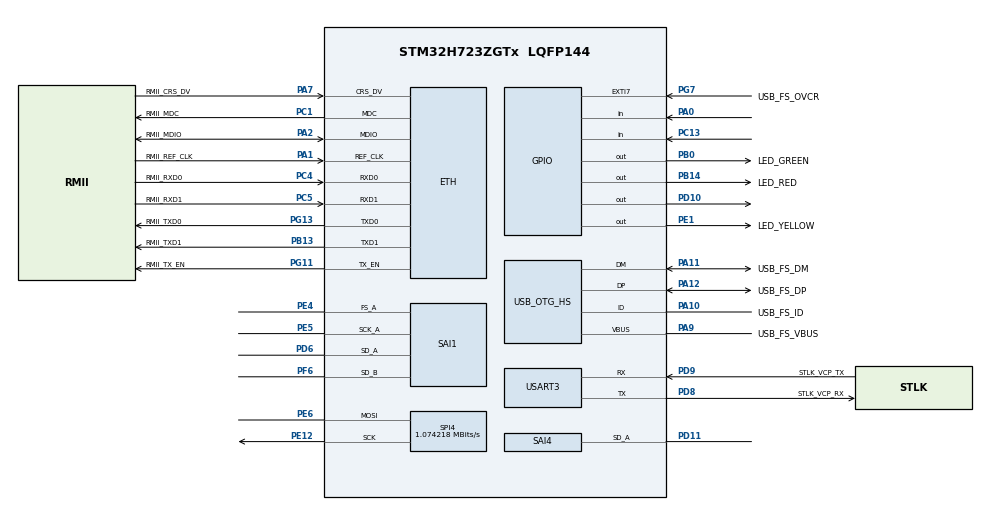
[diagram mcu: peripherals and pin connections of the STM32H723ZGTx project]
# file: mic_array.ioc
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Bdma.Request0=SAI4_A
Bdma.RequestsNb=1
Bdma.SAI4_A.0.Direction=DMA_PERIPH_TO_MEMORY
Bdma.SAI4_A.0.EventEnable=DISABLE
Bdma.SAI4_A.0.Instance=BDMA_Channel0
Bdma.SAI4_A.0.MemDataAlignment=DMA_MDATAALIGN_HALFWORD
Bdma.SAI4_A.0.MemInc=DMA_MINC_ENABLE
Bdma.SAI4_A.0.Mode=DMA_CIRCULAR
Bdma.SAI4_A.0.PeriphDataAlignment=DMA_PDATAALIGN_HALFWORD
Bdma.SAI4_A.0.PeriphInc=DMA_PINC_DISABLE
Bdma.SAI4_A.0.Polarity=HAL_DMAMUX_REQ_GEN_RISING
Bdma.SAI4_A.0.Priority=DMA_PRIORITY_LOW
Bdma.SAI4_A.0.RequestNumber=1
Bdma.SAI4_A.0.SignalID=NONE
Bdma.SAI4_A.0.SyncEnable=DISABLE
Bdma.SAI4_A.0.SyncPolarity=HAL_DMAMUX_SYNC_NO_EVENT
Bdma.SAI4_A.0.SyncRequestNumber=1
Bdma.SAI4_A.0.SyncSignalID=NONE
CORTEX_M7.AccessPermission-Cortex_Memory_Protection_Unit_Region0_Settings=MPU_REGION_FULL_ACCESS
CORTEX_M7.AccessPermission-Cortex_Memory_Protection_Unit_Region1_Settings=MPU_REGION_FULL_ACCESS
CORTEX_M7.BaseAddress-Cortex_Memory_Protection_Unit_Region0_Settings=0x30007000
CORTEX_M7.BaseAddress-Cortex_Memory_Protection_Unit_Region1_Settings=0x38003000
CORTEX_M7.CPU_DCache=Enabled
CORTEX_M7.CPU_ICache=Enabled
CORTEX_M7.DisableExec-Cortex_Memory_Protection_Unit_Region0_Settings=MPU_INSTRUCTION_ACCESS_DISABLE
CORTEX_M7.DisableExec-Cortex_Memory_Protection_Unit_Region1_Settings=MPU_INSTRUCTION_ACCESS_DISABLE
CORTEX_M7.Enable-Cortex_Memory_Protection_Unit_Region0_Settings=MPU_REGION_ENABLE
CORTEX_M7.Enable-Cortex_Memory_Protection_Unit_Region1_Settings=MPU_REGION_ENABLE
CORTEX_M7.IsShareable-Cortex_Memory_Protection_Unit_Region0_Settings=MPU_ACCESS_SHAREABLE
CORTEX_M7.IsShareable-Cortex_Memory_Protection_Unit_Region1_Settings=MPU_ACCESS_SHAREABLE
CORTEX_M7.MPU_Control=MPU_PRIVILEGED_DEFAULT
CORTEX_M7.Size-Cortex_Memory_Protection_Unit_Region0_Settings=MPU_REGION_SIZE_32KB
CORTEX_M7.Size-Cortex_Memory_Protection_Unit_Region1_Settings=MPU_REGION_SIZE_4KB
Dma.Request0=SAI1_A
Dma.Request1=SAI1_B
Dma.SAI1_A.0.Direction=DMA_PERIPH_TO_MEMORY
Dma.SAI1_A.0.EventEnable=DISABLE
Dma.SAI1_A.0.FIFOMode=DMA_FIFOMODE_DISABLE
Dma.SAI1_A.0.Instance=DMA1_Stream2
Dma.SAI1_A.0.MemDataAlignment=DMA_MDATAALIGN_HALFWORD
Dma.SAI1_A.0.MemInc=DMA_MINC_ENABLE
Dma.SAI1_A.0.Mode=DMA_CIRCULAR
Dma.SAI1_A.0.PeriphDataAlignment=DMA_PDATAALIGN_HALFWORD
Dma.SAI1_A.0.PeriphInc=DMA_PINC_DISABLE
Dma.SAI1_A.0.Polarity=HAL_DMAMUX_REQ_GEN_RISING
Dma.SAI1_A.0.Priority=DMA_PRIORITY_LOW
Dma.SAI1_A.0.RequestNumber=1
Dma.SAI1_A.0.SignalID=NONE
Dma.SAI1_A.0.SyncEnable=DISABLE
Dma.SAI1_A.0.SyncPolarity=HAL_DMAMUX_SYNC_NO_EVENT
Dma.SAI1_A.0.SyncRequestNumber=1
Dma.SAI1_A.0.SyncSignalID=NONE
Dma.SAI1_B.1.Direction=DMA_PERIPH_TO_MEMORY
Dma.SAI1_B.1.EventEnable=DISABLE
Dma.SAI1_B.1.FIFOMode=DMA_FIFOMODE_DISABLE
Dma.SAI1_B.1.Instance=DMA1_Stream3
Dma.SAI1_B.1.MemDataAlignment=DMA_MDATAALIGN_HALFWORD
Dma.SAI1_B.1.MemInc=DMA_MINC_ENABLE
Dma.SAI1_B.1.Mode=DMA_CIRCULAR
Dma.SAI1_B.1.PeriphDataAlignment=DMA_PDATAALIGN_HALFWORD
Dma.SAI1_B.1.PeriphInc=DMA_PINC_DISABLE
Dma.SAI1_B.1.Polarity=HAL_DMAMUX_REQ_GEN_RISING
Dma.SAI1_B.1.Priority=DMA_PRIORITY_LOW
Dma.SAI1_B.1.RequestNumber=1
Dma.SAI1_B.1.SignalID=NONE
Dma.SAI1_B.1.SyncEnable=DISABLE
Dma.SAI1_B.1.SyncPolarity=HAL_DMAMUX_SYNC_NO_EVENT
Dma.SAI1_B.1.SyncRequestNumber=1
Dma.SAI1_B.1.SyncSignalID=NONE
ETH.MediaInterface=HAL_ETH_RMII_MODE
Mcu.Family=STM32H7
Mcu.Name=STM32H723ZGTx
Mcu.Package=LQFP144
NVIC.BDMA_Channel0_IRQn=true\:0\:0\:false\:false\:true\:false\:true\:true
NVIC.DMA1_Stream2_IRQn=true\:0\:0\:false\:false\:true\:false\:true\:true
NVIC.DMA1_Stream3_IRQn=true\:0\:0\:false\:false\:true\:false\:true\:true
NVIC.PriorityGroup=NVIC_PRIORITYGROUP_4
NVIC.TIM1_UP_IRQn=true\:15\:0\:false\:false\:true\:false\:true\:true
NVIC.TimeBase=TIM1_UP_IRQn
NVIC.TimeBaseIP=TIM1
PA0.Signal=GPIO_Input
PA1.GPIO_Label=RMII_REF_CLK
PA1.Mode=RMII
PA1.Signal=ETH_REF_CLK
PA10.GPIO_Label=USB_FS_ID
PA10.Mode=OTG/Dual_Role_Device_FS
PA10.Signal=USB_OTG_HS_ID
PA11.GPIO_Label=USB_FS_DM
PA11.Mode=OTG/Dual_Role_Device_FS
PA11.Signal=USB_OTG_HS_DM
PA12.GPIO_Label=USB_FS_DP
PA12.Mode=OTG/Dual_Role_Device_FS
PA12.Signal=USB_OTG_HS_DP
PA13(JTMS/SWDIO).GPIO_Label=SWDIO
PA13(JTMS/SWDIO).Mode=Trace_Asynchronous_SW
PA13(JTMS/SWDIO).Signal=DEBUG_JTMS-SWDIO
PA14(JTCK/SWCLK).GPIO_Label=SWCLK
PA14(JTCK/SWCLK).Mode=Trace_Asynchronous_SW
PA14(JTCK/SWCLK).Signal=DEBUG_JTCK-SWCLK
PA15(JTDI).Signal=I2S6_WS
PA2.GPIO_Label=RMII_MDIO
PA2.Mode=RMII
PA2.Signal=ETH_MDIO
PA7.GPIO_Label=RMII_CRS_DV
PA7.Mode=RMII
PA7.Signal=ETH_CRS_DV
PA9.GPIO_Label=USB_FS_VBUS
PA9.Mode=Activate_VBUS_FS
PA9.Signal=USB_OTG_HS_VBUS
PB0.GPIO_Label=LED_GREEN
PB0.Signal=GPIO_Output
PB13.GPIO_Label=RMII_TXD1
PB13.Mode=RMII
PB13.Signal=ETH_TXD1
PB14.GPIO_Label=LED_RED
PB14.Signal=GPIO_Output
PB3(JTDO/TRACESWO).GPIO_Label=SWO
PB3(JTDO/TRACESWO).Mode=Trace_Asynchronous_SW
PB3(JTDO/TRACESWO).Signal=DEBUG_JTDO-SWO
PC1.GPIO_Label=RMII_MDC
PC1.Mode=RMII
PC1.Signal=ETH_MDC
PC13.Signal=GPIO_Input
PC14-OSC32_IN.Mode=LSE-External-Oscillator
PC14-OSC32_IN.Signal=RCC_OSC32_IN
PC15-OSC32_OUT.Mode=LSE-External-Oscillator
PC15-OSC32_OUT.Signal=RCC_OSC32_OUT
PC4.GPIO_Label=RMII_RXD0
PC4.Mode=RMII
PC4.Signal=ETH_RXD0
PC5.GPIO_Label=RMII_RXD1
PC5.Mode=RMII
PC5.Signal=ETH_RXD1
PD10.Signal=GPIO_Output
PD11.Mode=SAI_A_SyncSlave
PD11.Signal=SAI4_SD_A
PD6.Mode=SAI_A_Master
PD6.Signal=SAI1_SD_A
PD8.GPIO_Label=STLK_VCP_RX
PD8.Mode=Asynchronous
PD8.Signal=USART3_TX
PD9.GPIO_Label=STLK_VCP_TX
PD9.Mode=Asynchronous
PD9.Signal=USART3_RX
PE1.GPIO_Label=LED_YELLOW
PE1.Signal=GPIO_Output
PE12.Mode=Simplex_Bidirectional_Master
PE12.Signal=SPI4_SCK
PE4.Mode=SAI_A_Master
PE4.Signal=SAI1_FS_A
PE5.Mode=SAI_A_Master
PE5.Signal=SAI1_SCK_A
PE6.Mode=Simplex_Bidirectional_Master
PE6.Signal=SPI4_MOSI
PF6.Mode=SAI_B_SyncSlave
PF6.Signal=SAI1_SD_B
PG11.GPIO_Label=RMII_TX_EN
PG11.Mode=RMII
PG11.Signal=ETH_TX_EN
PG13.GPIO_Label=RMII_TXD0
PG13.Mode=RMII
PG13.Signal=ETH_TXD0
PG7.GPIO_Label=USB_FS_OVCR
PG7.Signal=GPXTI7
PH0-OSC_IN.GPIO_Label=MCO
PH0-OSC_IN.Mode=HSE-External-Clock-Source
PH0-OSC_IN.Signal=RCC_OSC_IN
PH1-OSC_OUT.Signal=RCC_OSC_OUT
ProjectManager.HeapSize=0x200
ProjectManager.StackSize=0x400
ProjectManager.TargetToolchain=STM32CubeIDE
RCC.ADCFreq_Value=76000000
RCC.APB1Freq_Value=137500000
RCC.APB2Freq_Value=137500000
RCC.APB3Freq_Value=137500000
RCC.APB4Freq_Value=137500000
RCC.CortexFreq_Value=550000000
RCC.D1PPRE=RCC_APB3_DIV2
RCC.D2PPRE1=RCC_APB1_DIV2
RCC.D2PPRE2=RCC_APB2_DIV2
RCC.D3PPRE=RCC_APB4_DIV2
RCC.DIVM1=4
RCC.DIVM2=1
RCC.DIVN1=275
RCC.DIVN2=19
RCC.DIVP1=1
RCC.DIVQ1=4
RCC.HCLKFreq_Value=275000000
RCC.HPRE=RCC_HCLK_DIV2
RCC.HSE_VALUE=8000000
RCC.PLLFRACN=0
RCC.PLLSourceVirtual=RCC_PLLSOURCE_HSE
RCC.SYSCLKFreq_VALUE=550000000
RCC.SYSCLKSource=RCC_SYSCLKSOURCE_PLLCLK
RCC.USBCLockSelection=RCC_USBCLKSOURCE_HSI48
RCC.USBFreq_Value=48000000
SAI1.AudioFrequency-SAI_A_Master=SAI_AUDIO_FREQUENCY_48K
SAI1.AudioMode-SAI_A_Master=SAI_MODEMASTER_RX
SAI1.BasicDataSize-SAI_A_Master=SAI_PROTOCOL_DATASIZE_16BITEXTENDED
SAI1.BasicDataSize-SAI_B_SyncSlave=SAI_PROTOCOL_DATASIZE_16BITEXTENDED
SAI1.BasicProtocol-SAI_A_Master=SAI_I2S_STANDARD
SAI1.ErrorAudioFreq-SAI_A_Master=11.89 %
SAI1.InitProtocol-SAI_A_Master=Enable
SAI1.InitProtocol-SAI_B_SyncSlave=Enable
SAI1.Instance-SAI_A_Master=SAI$Index_Block_A
SAI1.Instance-SAI_B_SyncSlave=SAI$Index_Block_B
SAI1.MckOutput-SAI_A_Master=SAI_MCK_OUTPUT_DISABLE
SAI1.RealAudioFreq-SAI_A_Master=53.71 KHz
SAI1.SynchroExt=SAI_SYNCEXT_OUTBLOCKA_ENABLE
SAI1.VirtualMode-SAI_A_Master=VM_MASTER
SAI1.VirtualMode-SAI_B_SyncSlave=VM_SLAVE
SAI1.VirtualProtocol-SAI_A_BASIC=VM_BASIC_PROTOCOL
SAI1.VirtualProtocol-SAI_B_BASIC=VM_BASIC_PROTOCOL
SAI4.BasicDataSize-SAI_A_SyncSlave=SAI_PROTOCOL_DATASIZE_16BITEXTENDED
SAI4.InitProtocol-SAI_A_SyncSlave=Enable
SAI4.Instance-SAI_A_SyncSlave=SAI$Index_Block_A
SAI4.Synchro_A=SAI_SYNCHRONOUS_EXT_SAI1
SAI4.VirtualMode-SAI_A_SyncSlave=VM_SLAVE
SAI4.VirtualProtocol-SAI_A_BASIC=VM_BASIC_PROTOCOL
SPI4.BaudRatePrescaler=SPI_BAUDRATEPRESCALER_128
SPI4.CalculateBaudRate=1.074218 MBits/s
SPI4.DataSize=SPI_DATASIZE_8BIT
SPI4.Direction=SPI_DIRECTION_1LINE
SPI4.Mode=SPI_MODE_MASTER
SPI4.VirtualType=VM_MASTER
USART3.VirtualMode-Asynchronous=VM_ASYNC
USB_OTG_HS.VirtualMode-OTG/Dual_Role_Device_FS=Device_Role_Device_FS
VP_MEMORYMAP_VS_MEMORYMAP.Mode=CurAppReg
VP_SAI1_VP_$IpInstance_SAIA_SAI_BASIC.Mode=SAI_A_BASIC
VP_SAI1_VP_$IpInstance_SAIB_SAI_BASIC.Mode=SAI_B_BASIC
VP_SAI1_VP_$IpInstance_SYNCHRO_EXTERNAL.Mode=SynchroExternal
VP_SAI4_VP_$IpInstance_SAIA_SAI_BASIC.Mode=SAI_A_BASIC
VP_SYS_VS_tim1.Mode=TIM1
VP_USB_OTG_HS1_USB_OTG_HS_DR.Mode=activate
board=NUCLEO-H723ZG

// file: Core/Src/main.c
/* USER CODE BEGIN Header */
/**
 ******************************************************************************
 * @file           : main.c
 * @brief          : Main program body
 ******************************************************************************
 * @attention
 *
 * Copyright (c) 2026 STMicroelectronics.
 * All rights reserved.
 *
 * This software is licensed under terms that can be found in the LICENSE file
 * in the root directory of this software component.
 * If no LICENSE file comes with this software, it is provided AS-IS.
 *
 ******************************************************************************
 */
/* USER CODE END Header */
#include "main.h"
#include "string.h"

/* USER CODE BEGIN Includes */
//#include "app.h"
#include "app_mic_test.h"

/* USER CODE END Includes */

#if defined ( __ICCARM__ ) /*!< IAR Compiler */
#pragma location=0x30000000
ETH_DMADescTypeDef  DMARxDscrTab[ETH_RX_DESC_CNT]; /* Ethernet Rx DMA Descriptors */
#pragma location=0x30000080
ETH_DMADescTypeDef  DMATxDscrTab[ETH_TX_DESC_CNT]; /* Ethernet Tx DMA Descriptors */

#elif defined ( __CC_ARM )  /* MDK ARM Compiler */

__attribute__((at(0x30000000))) ETH_DMADescTypeDef  DMARxDscrTab[ETH_RX_DESC_CNT]; /* Ethernet Rx DMA Descriptors */
__attribute__((at(0x30000080))) ETH_DMADescTypeDef  DMATxDscrTab[ETH_TX_DESC_CNT]; /* Ethernet Tx DMA Descriptors */

#elif defined ( __GNUC__ ) /* GNU Compiler */

ETH_DMADescTypeDef DMARxDscrTab[ETH_RX_DESC_CNT] __attribute__((section(".RxDescripSection"))); /* Ethernet Rx DMA Descriptors */
ETH_DMADescTypeDef DMATxDscrTab[ETH_TX_DESC_CNT] __attribute__((section(".TxDescripSection")));   /* Ethernet Tx DMA Descriptors */
#endif

ETH_TxPacketConfig TxConfig;

ETH_HandleTypeDef heth;

SAI_HandleTypeDef hsai_BlockA1;
SAI_HandleTypeDef hsai_BlockB1;
SAI_HandleTypeDef hsai_BlockA4;
DMA_HandleTypeDef hdma_sai1_a;
DMA_HandleTypeDef hdma_sai1_b;
DMA_HandleTypeDef hdma_sai4_a;

SPI_HandleTypeDef hspi4;

UART_HandleTypeDef huart3;

PCD_HandleTypeDef hpcd_USB_OTG_HS;
HCD_HandleTypeDef hhcd_USB_OTG_HS;

void SystemClock_Config(void);
static void MPU_Config(void);
static void MX_GPIO_Init(void);
static void MX_DMA_Init(void);
static void MX_BDMA_Init(void);
static void MX_ETH_Init(void);
static void MX_USART3_UART_Init(void);
static void MX_USB_OTG_HS_PCD_Init(void);
static void MX_SPI4_Init(void);
static void MX_SAI1_Init(void);
static void MX_SAI4_Init(void);

int main(void)
{

  /* MPU Configuration--------------------------------------------------------*/
  MPU_Config();

  /* Enable the CPU Cache */

  /* Enable I-Cache---------------------------------------------------------*/
  SCB_EnableICache();

  /* Enable D-Cache---------------------------------------------------------*/
  SCB_EnableDCache();

  /* MCU Configuration--------------------------------------------------------*/

  /* Reset of all peripherals, Initializes the Flash interface and the Systick. */
  HAL_Init();

  /* Configure the system clock */
  SystemClock_Config();

  /* USER CODE BEGIN SysInit */

  // Ensure D3 memory region stays powered on when I'm debugging
  PWR->CPUCR |= PWR_CPUCR_RUN_D3;

  /* USER CODE END SysInit */

  /* Initialize all configured peripherals */
  MX_GPIO_Init();
  MX_DMA_Init();
  MX_BDMA_Init();
  MX_ETH_Init();
  MX_USART3_UART_Init();
  MX_USB_OTG_HS_PCD_Init();
  MX_SPI4_Init();
  MX_SAI1_Init();
  MX_SAI4_Init();
  /* USER CODE BEGIN 2 */

  HAL_StatusTypeDef ret = app_init();
  if (ret != HAL_OK)
  {
      while (1)
      {

      }
  }

  /* USER CODE END 2 */

  /* Infinite loop */
  /* USER CODE BEGIN WHILE */
    app_loop();
    /* USER CODE END WHILE */

}

void SystemClock_Config(void)
{
  RCC_OscInitTypeDef RCC_OscInitStruct = {0};
  RCC_ClkInitTypeDef RCC_ClkInitStruct = {0};

  /** Supply configuration update enable
  */
  HAL_PWREx_ConfigSupply(PWR_LDO_SUPPLY);

  /** Configure the main internal regulator output voltage
  */
  __HAL_PWR_VOLTAGESCALING_CONFIG(PWR_REGULATOR_VOLTAGE_SCALE0);

  while(!__HAL_PWR_GET_FLAG(PWR_FLAG_VOSRDY)) {}

  /** Initializes the RCC Oscillators according to the specified parameters
  * in the RCC_OscInitTypeDef structure.
  */
  RCC_OscInitStruct.OscillatorType = RCC_OSCILLATORTYPE_HSI48|RCC_OSCILLATORTYPE_HSE;
  RCC_OscInitStruct.HSEState = RCC_HSE_BYPASS;
  RCC_OscInitStruct.HSI48State = RCC_HSI48_ON;
  RCC_OscInitStruct.PLL.PLLState = RCC_PLL_ON;
  RCC_OscInitStruct.PLL.PLLSource = RCC_PLLSOURCE_HSE;
  RCC_OscInitStruct.PLL.PLLM = 4;
  RCC_OscInitStruct.PLL.PLLN = 275;
  RCC_OscInitStruct.PLL.PLLP = 1;
  RCC_OscInitStruct.PLL.PLLQ = 4;
  RCC_OscInitStruct.PLL.PLLR = 2;
  RCC_OscInitStruct.PLL.PLLRGE = RCC_PLL1VCIRANGE_1;
  RCC_OscInitStruct.PLL.PLLVCOSEL = RCC_PLL1VCOWIDE;
  RCC_OscInitStruct.PLL.PLLFRACN = 0;
  if (HAL_RCC_OscConfig(&RCC_OscInitStruct) != HAL_OK)
  {
    Error_Handler();
  }

  /** Initializes the CPU, AHB and APB buses clocks
  */
  RCC_ClkInitStruct.ClockType = RCC_CLOCKTYPE_HCLK|RCC_CLOCKTYPE_SYSCLK
                              |RCC_CLOCKTYPE_PCLK1|RCC_CLOCKTYPE_PCLK2
                              |RCC_CLOCKTYPE_D3PCLK1|RCC_CLOCKTYPE_D1PCLK1;
  RCC_ClkInitStruct.SYSCLKSource = RCC_SYSCLKSOURCE_PLLCLK;
  RCC_ClkInitStruct.SYSCLKDivider = RCC_SYSCLK_DIV1;
  RCC_ClkInitStruct.AHBCLKDivider = RCC_HCLK_DIV2;
  RCC_ClkInitStruct.APB3CLKDivider = RCC_APB3_DIV2;
  RCC_ClkInitStruct.APB1CLKDivider = RCC_APB1_DIV2;
  RCC_ClkInitStruct.APB2CLKDivider = RCC_APB2_DIV2;
  RCC_ClkInitStruct.APB4CLKDivider = RCC_APB4_DIV2;

  if (HAL_RCC_ClockConfig(&RCC_ClkInitStruct, FLASH_LATENCY_3) != HAL_OK)
  {
    Error_Handler();
  }
}

static void MX_ETH_Init(void)
{

   static uint8_t MACAddr[6];

  heth.Instance = ETH;
  MACAddr[0] = 0x00;
  MACAddr[1] = 0x80;
  MACAddr[2] = 0xE1;
  MACAddr[3] = 0x00;
  MACAddr[4] = 0x00;
  MACAddr[5] = 0x00;
  heth.Init.MACAddr = &MACAddr[0];
  heth.Init.MediaInterface = HAL_ETH_RMII_MODE;
  heth.Init.TxDesc = DMATxDscrTab;
  heth.Init.RxDesc = DMARxDscrTab;
  heth.Init.RxBuffLen = 1536;

  if (HAL_ETH_Init(&heth) != HAL_OK)
  {
    Error_Handler();
  }

  memset(&TxConfig, 0 , sizeof(ETH_TxPacketConfig));
  TxConfig.Attributes = ETH_TX_PACKETS_FEATURES_CSUM | ETH_TX_PACKETS_FEATURES_CRCPAD;
  TxConfig.ChecksumCtrl = ETH_CHECKSUM_IPHDR_PAYLOAD_INSERT_PHDR_CALC;
  TxConfig.CRCPadCtrl = ETH_CRC_PAD_INSERT;

}

static void MX_SAI1_Init(void)
{

  hsai_BlockA1.Instance = SAI1_Block_A;
  hsai_BlockA1.Init.AudioMode = SAI_MODEMASTER_RX;
  hsai_BlockA1.Init.Synchro = SAI_ASYNCHRONOUS;
  hsai_BlockA1.Init.OutputDrive = SAI_OUTPUTDRIVE_DISABLE;
  hsai_BlockA1.Init.NoDivider = SAI_MASTERDIVIDER_ENABLE;
  hsai_BlockA1.Init.FIFOThreshold = SAI_FIFOTHRESHOLD_EMPTY;
  hsai_BlockA1.Init.AudioFrequency = SAI_AUDIO_FREQUENCY_48K;
  hsai_BlockA1.Init.SynchroExt = SAI_SYNCEXT_OUTBLOCKA_ENABLE;
  hsai_BlockA1.Init.MonoStereoMode = SAI_STEREOMODE;
  hsai_BlockA1.Init.CompandingMode = SAI_NOCOMPANDING;
  if (HAL_SAI_InitProtocol(&hsai_BlockA1, SAI_I2S_STANDARD, SAI_PROTOCOL_DATASIZE_16BITEXTENDED, 2) != HAL_OK)
  {
    Error_Handler();
  }
  hsai_BlockB1.Instance = SAI1_Block_B;
  hsai_BlockB1.Init.AudioMode = SAI_MODESLAVE_RX;
  hsai_BlockB1.Init.Synchro = SAI_SYNCHRONOUS;
  hsai_BlockB1.Init.OutputDrive = SAI_OUTPUTDRIVE_DISABLE;
  hsai_BlockB1.Init.FIFOThreshold = SAI_FIFOTHRESHOLD_EMPTY;
  hsai_BlockB1.Init.SynchroExt = SAI_SYNCEXT_OUTBLOCKA_ENABLE;
  hsai_BlockB1.Init.MonoStereoMode = SAI_STEREOMODE;
  hsai_BlockB1.Init.CompandingMode = SAI_NOCOMPANDING;
  hsai_BlockB1.Init.TriState = SAI_OUTPUT_NOTRELEASED;
  if (HAL_SAI_InitProtocol(&hsai_BlockB1, SAI_I2S_STANDARD, SAI_PROTOCOL_DATASIZE_16BITEXTENDED, 2) != HAL_OK)
  {
    Error_Handler();
  }

}

static void MX_SAI4_Init(void)
{

  hsai_BlockA4.Instance = SAI4_Block_A;
  hsai_BlockA4.Init.AudioMode = SAI_MODESLAVE_RX;
  hsai_BlockA4.Init.Synchro = SAI_SYNCHRONOUS_EXT_SAI1;
  hsai_BlockA4.Init.OutputDrive = SAI_OUTPUTDRIVE_DISABLE;
  hsai_BlockA4.Init.FIFOThreshold = SAI_FIFOTHRESHOLD_EMPTY;
  hsai_BlockA4.Init.MonoStereoMode = SAI_STEREOMODE;
  hsai_BlockA4.Init.CompandingMode = SAI_NOCOMPANDING;
  hsai_BlockA4.Init.TriState = SAI_OUTPUT_NOTRELEASED;
  if (HAL_SAI_InitProtocol(&hsai_BlockA4, SAI_I2S_STANDARD, SAI_PROTOCOL_DATASIZE_16BITEXTENDED, 2) != HAL_OK)
  {
    Error_Handler();
  }

}

static void MX_SPI4_Init(void)
{

  /* SPI4 parameter configuration*/
  hspi4.Instance = SPI4;
  hspi4.Init.Mode = SPI_MODE_MASTER;
  hspi4.Init.Direction = SPI_DIRECTION_1LINE;
  hspi4.Init.DataSize = SPI_DATASIZE_8BIT;
  hspi4.Init.CLKPolarity = SPI_POLARITY_LOW;
  hspi4.Init.CLKPhase = SPI_PHASE_1EDGE;
  hspi4.Init.NSS = SPI_NSS_SOFT;
  hspi4.Init.BaudRatePrescaler = SPI_BAUDRATEPRESCALER_128;
  hspi4.Init.FirstBit = SPI_FIRSTBIT_MSB;
  hspi4.Init.TIMode = SPI_TIMODE_DISABLE;
  hspi4.Init.CRCCalculation = SPI_CRCCALCULATION_DISABLE;
  hspi4.Init.CRCPolynomial = 0x0;
  hspi4.Init.NSSPMode = SPI_NSS_PULSE_ENABLE;
  hspi4.Init.NSSPolarity = SPI_NSS_POLARITY_LOW;
  hspi4.Init.FifoThreshold = SPI_FIFO_THRESHOLD_01DATA;
  hspi4.Init.TxCRCInitializationPattern = SPI_CRC_INITIALIZATION_ALL_ZERO_PATTERN;
  hspi4.Init.RxCRCInitializationPattern = SPI_CRC_INITIALIZATION_ALL_ZERO_PATTERN;
  hspi4.Init.MasterSSIdleness = SPI_MASTER_SS_IDLENESS_00CYCLE;
  hspi4.Init.MasterInterDataIdleness = SPI_MASTER_INTERDATA_IDLENESS_00CYCLE;
  hspi4.Init.MasterReceiverAutoSusp = SPI_MASTER_RX_AUTOSUSP_DISABLE;
  hspi4.Init.MasterKeepIOState = SPI_MASTER_KEEP_IO_STATE_DISABLE;
  hspi4.Init.IOSwap = SPI_IO_SWAP_DISABLE;
  if (HAL_SPI_Init(&hspi4) != HAL_OK)
  {
    Error_Handler();
  }

}

static void MX_USART3_UART_Init(void)
{

  huart3.Instance = USART3;
  huart3.Init.BaudRate = 115200;
  huart3.Init.WordLength = UART_WORDLENGTH_8B;
  huart3.Init.StopBits = UART_STOPBITS_1;
  huart3.Init.Parity = UART_PARITY_NONE;
  huart3.Init.Mode = UART_MODE_TX_RX;
  huart3.Init.HwFlowCtl = UART_HWCONTROL_NONE;
  huart3.Init.OverSampling = UART_OVERSAMPLING_16;
  huart3.Init.OneBitSampling = UART_ONE_BIT_SAMPLE_DISABLE;
  huart3.Init.ClockPrescaler = UART_PRESCALER_DIV1;
  huart3.AdvancedInit.AdvFeatureInit = UART_ADVFEATURE_NO_INIT;
  if (HAL_UART_Init(&huart3) != HAL_OK)
  {
    Error_Handler();
  }
  if (HAL_UARTEx_SetTxFifoThreshold(&huart3, UART_TXFIFO_THRESHOLD_1_8) != HAL_OK)
  {
    Error_Handler();
  }
  if (HAL_UARTEx_SetRxFifoThreshold(&huart3, UART_RXFIFO_THRESHOLD_1_8) != HAL_OK)
  {
    Error_Handler();
  }
  if (HAL_UARTEx_DisableFifoMode(&huart3) != HAL_OK)
  {
    Error_Handler();
  }

}

static void MX_USB_OTG_HS_PCD_Init(void)
{

  hpcd_USB_OTG_HS.Instance = USB_OTG_HS;
  hpcd_USB_OTG_HS.Init.dev_endpoints = 9;
  hpcd_USB_OTG_HS.Init.speed = PCD_SPEED_FULL;
  hpcd_USB_OTG_HS.Init.dma_enable = DISABLE;
  hpcd_USB_OTG_HS.Init.phy_itface = USB_OTG_EMBEDDED_PHY;
  hpcd_USB_OTG_HS.Init.Sof_enable = DISABLE;
  hpcd_USB_OTG_HS.Init.low_power_enable = DISABLE;
  hpcd_USB_OTG_HS.Init.lpm_enable = DISABLE;
  hpcd_USB_OTG_HS.Init.vbus_sensing_enable = ENABLE;
  hpcd_USB_OTG_HS.Init.use_dedicated_ep1 = DISABLE;
  hpcd_USB_OTG_HS.Init.use_external_vbus = DISABLE;
  if (HAL_PCD_Init(&hpcd_USB_OTG_HS) != HAL_OK)
  {
    Error_Handler();
  }

}

void MX_USB_OTG_HS_HCD_Init(void)
{

  hhcd_USB_OTG_HS.Instance = USB_OTG_HS;
  hhcd_USB_OTG_HS.Init.Host_channels = 16;
  hhcd_USB_OTG_HS.Init.speed = HCD_SPEED_FULL;
  hhcd_USB_OTG_HS.Init.dma_enable = DISABLE;
  hhcd_USB_OTG_HS.Init.phy_itface = USB_OTG_EMBEDDED_PHY;
  hhcd_USB_OTG_HS.Init.Sof_enable = DISABLE;
  hhcd_USB_OTG_HS.Init.low_power_enable = DISABLE;
  if (HAL_HCD_Init(&hhcd_USB_OTG_HS) != HAL_OK)
  {
    Error_Handler();
  }

}

static void MX_BDMA_Init(void)
{

  /* DMA controller clock enable */
  __HAL_RCC_BDMA_CLK_ENABLE();

  /* DMA interrupt init */
  /* BDMA_Channel0_IRQn interrupt configuration */
  HAL_NVIC_SetPriority(BDMA_Channel0_IRQn, 0, 0);
  HAL_NVIC_EnableIRQ(BDMA_Channel0_IRQn);

}

static void MX_DMA_Init(void)
{

  /* DMA controller clock enable */
  __HAL_RCC_DMA1_CLK_ENABLE();

  /* DMA interrupt init */
  /* DMA1_Stream2_IRQn interrupt configuration */
  HAL_NVIC_SetPriority(DMA1_Stream2_IRQn, 0, 0);
  HAL_NVIC_EnableIRQ(DMA1_Stream2_IRQn);
  /* DMA1_Stream3_IRQn interrupt configuration */
  HAL_NVIC_SetPriority(DMA1_Stream3_IRQn, 0, 0);
  HAL_NVIC_EnableIRQ(DMA1_Stream3_IRQn);

}

static void MX_GPIO_Init(void)
{
  GPIO_InitTypeDef GPIO_InitStruct = {0};

  /* GPIO Ports Clock Enable */
  __HAL_RCC_GPIOE_CLK_ENABLE();
  __HAL_RCC_GPIOC_CLK_ENABLE();
  __HAL_RCC_GPIOF_CLK_ENABLE();
  __HAL_RCC_GPIOH_CLK_ENABLE();
  __HAL_RCC_GPIOA_CLK_ENABLE();
  __HAL_RCC_GPIOB_CLK_ENABLE();
  __HAL_RCC_GPIOD_CLK_ENABLE();
  __HAL_RCC_GPIOG_CLK_ENABLE();

  /*Configure GPIO pin Output Level */
  HAL_GPIO_WritePin(GPIOB, LED_GREEN_Pin|LED_RED_Pin, GPIO_PIN_RESET);

  /*Configure GPIO pin Output Level */
  HAL_GPIO_WritePin(GPIOD, GPIO_PIN_10, GPIO_PIN_RESET);

  /*Configure GPIO pin Output Level */
  HAL_GPIO_WritePin(LED_YELLOW_GPIO_Port, LED_YELLOW_Pin, GPIO_PIN_RESET);

  /*Configure GPIO pin : PC13 */
  GPIO_InitStruct.Pin = GPIO_PIN_13;
  GPIO_InitStruct.Mode = GPIO_MODE_INPUT;
  GPIO_InitStruct.Pull = GPIO_NOPULL;
  HAL_GPIO_Init(GPIOC, &GPIO_InitStruct);

  /*Configure GPIO pin : PA0 */
  GPIO_InitStruct.Pin = GPIO_PIN_0;
  GPIO_InitStruct.Mode = GPIO_MODE_INPUT;
  GPIO_InitStruct.Pull = GPIO_NOPULL;
  HAL_GPIO_Init(GPIOA, &GPIO_InitStruct);

  /*Configure GPIO pins : LED_GREEN_Pin LED_RED_Pin */
  GPIO_InitStruct.Pin = LED_GREEN_Pin|LED_RED_Pin;
  GPIO_InitStruct.Mode = GPIO_MODE_OUTPUT_PP;
  GPIO_InitStruct.Pull = GPIO_NOPULL;
  GPIO_InitStruct.Speed = GPIO_SPEED_FREQ_LOW;
  HAL_GPIO_Init(GPIOB, &GPIO_InitStruct);

  /*Configure GPIO pin : PD10 */
  GPIO_InitStruct.Pin = GPIO_PIN_10;
  GPIO_InitStruct.Mode = GPIO_MODE_OUTPUT_PP;
  GPIO_InitStruct.Pull = GPIO_NOPULL;
  GPIO_InitStruct.Speed = GPIO_SPEED_FREQ_LOW;
  HAL_GPIO_Init(GPIOD, &GPIO_InitStruct);

  /*Configure GPIO pin : USB_FS_OVCR_Pin */
  GPIO_InitStruct.Pin = USB_FS_OVCR_Pin;
  GPIO_InitStruct.Mode = GPIO_MODE_IT_RISING;
  GPIO_InitStruct.Pull = GPIO_NOPULL;
  HAL_GPIO_Init(USB_FS_OVCR_GPIO_Port, &GPIO_InitStruct);

  /*Configure GPIO pin : PA15 */
  GPIO_InitStruct.Pin = GPIO_PIN_15;
  GPIO_InitStruct.Mode = GPIO_MODE_AF_PP;
  GPIO_InitStruct.Pull = GPIO_NOPULL;
  GPIO_InitStruct.Speed = GPIO_SPEED_FREQ_LOW;
  GPIO_InitStruct.Alternate = GPIO_AF7_SPI6;
  HAL_GPIO_Init(GPIOA, &GPIO_InitStruct);

  /*Configure GPIO pin : LED_YELLOW_Pin */
  GPIO_InitStruct.Pin = LED_YELLOW_Pin;
  GPIO_InitStruct.Mode = GPIO_MODE_OUTPUT_PP;
  GPIO_InitStruct.Pull = GPIO_NOPULL;
  GPIO_InitStruct.Speed = GPIO_SPEED_FREQ_LOW;
  HAL_GPIO_Init(LED_YELLOW_GPIO_Port, &GPIO_InitStruct);

}

/* USER CODE BEGIN 4 */
// Override system call to route "printf" calls over the ST-Link to the PC
int __io_putchar(int ch) {
    HAL_UART_Transmit(&huart3, (uint8_t *)&ch, 1, HAL_MAX_DELAY);
    return ch;
}

/* USER CODE END 4 */

 /* MPU Configuration */

void MPU_Config(void)
{
  MPU_Region_InitTypeDef MPU_InitStruct = {0};

  /* Disables the MPU */
  HAL_MPU_Disable();

  /** Initializes and configures the Region and the memory to be protected
  */
  MPU_InitStruct.Enable = MPU_REGION_ENABLE;
  MPU_InitStruct.Number = MPU_REGION_NUMBER0;
  MPU_InitStruct.BaseAddress = 0x30007000;
  MPU_InitStruct.Size = MPU_REGION_SIZE_32KB;
  MPU_InitStruct.SubRegionDisable = 0x0;
  MPU_InitStruct.TypeExtField = MPU_TEX_LEVEL0;
  MPU_InitStruct.AccessPermission = MPU_REGION_FULL_ACCESS;
  MPU_InitStruct.DisableExec = MPU_INSTRUCTION_ACCESS_DISABLE;
  MPU_InitStruct.IsShareable = MPU_ACCESS_SHAREABLE;
  MPU_InitStruct.IsCacheable = MPU_ACCESS_NOT_CACHEABLE;
  MPU_InitStruct.IsBufferable = MPU_ACCESS_NOT_BUFFERABLE;

  HAL_MPU_ConfigRegion(&MPU_InitStruct);

  /** Initializes and configures the Region and the memory to be protected
  */
  MPU_InitStruct.Number = MPU_REGION_NUMBER1;
  MPU_InitStruct.BaseAddress = 0x38003000;
  MPU_InitStruct.Size = MPU_REGION_SIZE_4KB;

  HAL_MPU_ConfigRegion(&MPU_InitStruct);
  /* Enables the MPU */
  HAL_MPU_Enable(MPU_PRIVILEGED_DEFAULT);

}

void HAL_TIM_PeriodElapsedCallback(TIM_HandleTypeDef *htim)
{
  if (htim->Instance == TIM1)
  {
    HAL_IncTick();
  }
}

void Error_Handler(void)
{
    __disable_irq();
    while (1) {
    }
}
